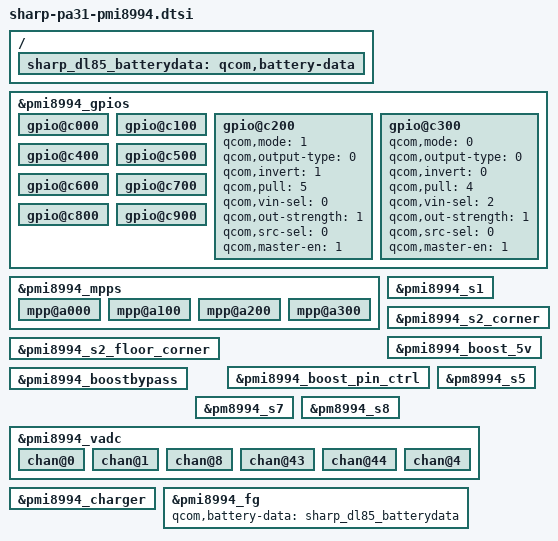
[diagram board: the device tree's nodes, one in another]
/* Copyright (c) 2014, The Linux Foundation. All rights reserved.
 *
 * This program is free software; you can redistribute it and/or modify
 * it under the terms of the GNU General Public License version 2 and
 * only version 2 as published by the Free Software Foundation.
 *
 * This program is distributed in the hope that it will be useful,
 * but WITHOUT ANY WARRANTY; without even the implied warranty of
 * MERCHANTABILITY or FITNESS FOR A PARTICULAR PURPOSE.  See the
 * GNU General Public License for more details.
 */

#include "sharp-pa31-chg-param.dtsi"

/*****************************************/
/*  pmi8994-gpios: qpnp-pin               */
/*****************************************/

&pmi8994_gpios {

	gpio@c000 { /* GPIO_01 */
	};

	gpio@c100 { /* GPIO_02 */
	};

	gpio@c200 { /* GPIO_03 */
		/* FP_POW_EN (Fever3.0)/NFC_HSEL (Fever2.0) */
		qcom,mode = <1>;			/* DIG_OUT */
		qcom,output-type = <0>;		/* CMOS */
		qcom,invert = <1>;			/* ENABLE */
		qcom,pull = <5>;			/* NO_PULL */
		qcom,vin-sel = <0>;			/* VPH_PWR */
		qcom,out-strength = <1>;	/* LOW */
		qcom,src-sel = <0>;			/* CONSTANT */
		qcom,master-en = <1>;		/* ENABLE */
		status = "okay";
	};

	gpio@c300 { /* GPIO_04 */
		/* NC */
		qcom,mode = <0>;			/* DIG_IN */
		qcom,output-type = <0>;		/* CMOS */
		qcom,invert = <0>;			/* DISABLE */
		qcom,pull = <4>;			/* PULL_DN */
		qcom,vin-sel = <2>;			/* S4 */
		qcom,out-strength = <1>;	/* LOW */
		qcom,src-sel = <0>;			/* CONSTANT */
		qcom,master-en = <1>;		/* ENABLE */
		status = "okay";
	};

	gpio@c400 { /* GPIO_05 */
	};

	gpio@c500 { /* GPIO_06 */
	};

	gpio@c600 { /* GPIO_07 */
	};

	gpio@c700 { /* GPIO_08 */
	};

	gpio@c800 { /* GPIO_09 */
	};

	gpio@c900 { /* GPIO_10 */
	};
};
/*****************************************/
/*  pmi8994-mpps: qpnp-pin                */
/*****************************************/

&pmi8994_mpps {

	mpp@a000 { /* MPP_01 */

	};

	mpp@a100 { /* MPP_02 */
	};

	mpp@a200 { /* MPP_03 */
	};

	mpp@a300 { /* MPP_04 */
	};
};
/*****************************************/
/*  pmi8994: rpm-regulator                */
/*****************************************/
&pmi8994_s1 { /* pmi8994_s1 */
};

&pmi8994_s2_corner { /* pmi8994_s2_corner */
};

&pmi8994_s2_floor_corner { /* pmi8994_s2_floor_corner */
};

&pmi8994_boost_5v { /* pmi8994_boost_5v: */
};

&pmi8994_boost_pin_ctrl { /* pmi8994_boost_pin_ctrl: */
};

&pmi8994_boostbypass { /* pmi8994_boostbypass */
};

&pm8994_s5 { /* 8994_s5 */
};

&pm8994_s7 { /* 8994_s7 */
};
/* PM8994 S8 = VDD_APC0 supply */
&pm8994_s8 { /* 8994_s8 */
};

/*****************************************/
/*  qpnp-adc-voltage                     */
/*****************************************/

&pmi8994_vadc {
	chan@0 { /* usbin */
	};

	chan@1 { /* dcin */
	};
	
	chan@8 { /* die_temp */
	};
	
	chan@43 { /* usb_dp */
	};

	chan@44 { /* usb_dm */
	};

	chan@4 { /* usb_id */
	};
};

/*****************************************/
/*  pmi8994_charger                     */
/*****************************************/
&pmi8994_charger {
};


/{
	sharp_dl85_batterydata: qcom,battery-data {
		#include "batterydata-sharp-dl85.dtsi"
	};
};
/*****************************************/
/*  pmi8994_fg                           */
/*****************************************/
&pmi8994_fg {
	qcom,battery-data = <&sharp_dl85_batterydata>;
};
